# NANO100AN_v1 register map
File version: 1.0
Registers are 32-bit, read-write, reset 0x0 unless marked. A register's access mark holds for its fields unless they carry their own. Offsets are from the block's base; [hi:lo] are bit positions; {n}, {i} and the like mark numbered series; 'fields as' and 'values as' point back to an identical list.

## PWM1 — PWM Register Map
Base 0x40140000
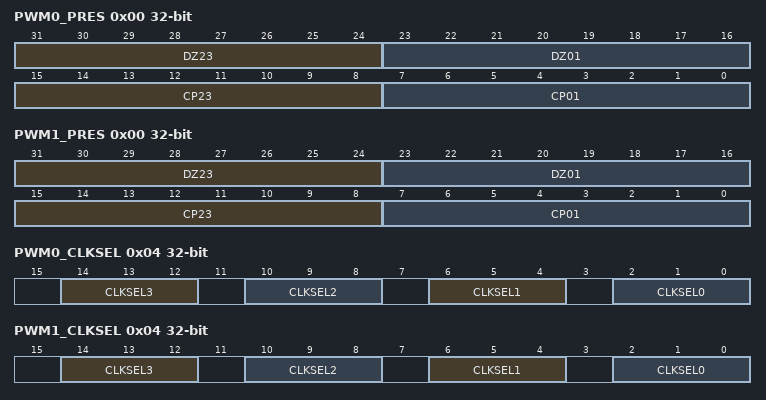
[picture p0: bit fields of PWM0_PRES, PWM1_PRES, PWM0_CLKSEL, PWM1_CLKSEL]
0x00 PWM0_PRES — PWM Prescaler Register
  [31:24] DZ23 — Dead Zone Interval Register For CH2 And CH3 Pair. These 8 bits determine dead zone length. The unit time of dead zone length is received from clock selector 2.
  [23:16] DZ01 — Dead Zone Interval Register For CH0 And CH1 Pair. These 8 bits determine dead zone length. The unit time of dead zone length is received from clock selector 0.
  [15:8] CP23 — Clock Prescaler 2 For PWM Timer 2 3. Clock input is divided by (CP23 + 1) before it is fed to the counter 2 3
  [7:0] CP01 — Clock Prescaler 0 For PWM Timer 0 1. Clock input is divided by (CP01 + 1) before it is fed to the counter 0 1
0x00 PWM1_PRES (alternate view of PWM0_PRES) — PWM Prescaler Register
  fields as PWM0_PRES
0x04 PWM0_CLKSEL — PWM Clock Select Register
  [14:12] CLKSEL3 — Timer 3 Clock Source Selection. Select clock input for timer 3.
    0=input clock is divided by 2; 1=input clock is divided by 4; 2=input clock is divided by 8; 3=input clock is divided by 16; 4=input clock is divided by 1
  [10:8] CLKSEL2 — Timer 2Clock Source Selection. Select clock input for timer 2. (Table is the same as CLKSEL3)
  [6:4] CLKSEL1 — Timer 1 Clock Source Selection. Select clock input for timer 1. (Table is the same as CLKSEL3)
  [2:0] CLKSEL0 — Timer 0 Clock Source Selection. Select clock input for timer 0. (Table is the same as CLKSEL3)
0x04 PWM1_CLKSEL (alternate view of PWM0_CLKSEL) — PWM Clock Select Register
  fields as PWM0_CLKSEL
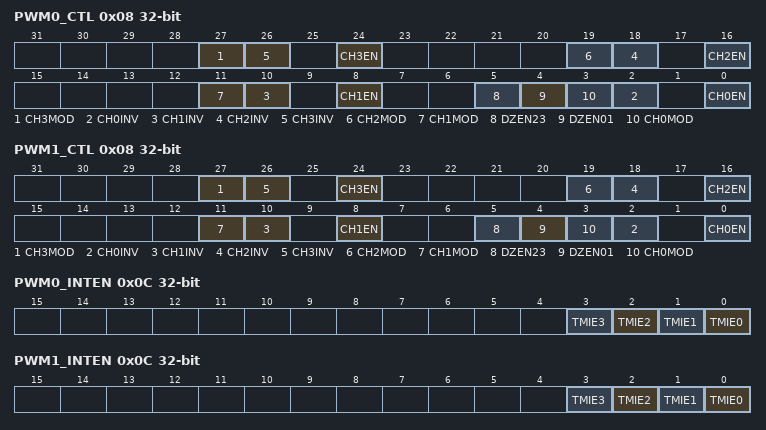
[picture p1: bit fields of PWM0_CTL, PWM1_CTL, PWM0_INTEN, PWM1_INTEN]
0x08 PWM0_CTL — PWM Control Register
  [27] CH3MOD — PWM-Timer 3 Continuous/One-Shot Mode. Note: If there is a rising transition at this bit, it will cause CN and CM of PWMx_DUTY3 to be cleared.
    0=One-shot Mode; 1=Continuous Mode
  [8n+2] CH{n}INV (n=0..3) — PWM-Timer {n} Output Inverter ON/OFF
    0=Inverter OFF; 1=Inverter ON
  [8n] CH{n}EN (n=0..3) — PWM-Timer {n} Enable/Disable Start Run
    0=PWM-Timer {n} Running Stopped; 1=PWM-Timer {n} Start Run Enabled
  [19] CH2MOD — PWM-Timer 2 Continuous/One-Shot Mode. Note: If there is a rising transition at this bit, it will cause CN and CM of PWMx_DUTY2 be cleared.
    0=One-shot Mode; 1=Continuous Mode
  [11] CH1MOD — PWM-Timer 1 Continuous/One-Shot Mode. Note: If there is a rising transition at this bit, it will cause CN and CM of PWMx_DUTY1 to be cleared.
    0=One-shot Mode; 1=Continuous Mode
  [5] DZEN23 — Dead-Zone 2 Generator Enable/Disable. Note: When Dead-Zone Generator is enabled, the pair of PWM2 and PWM3 becomes a complementary pair.
    0=Disabled; 1=Enabled
  [4] DZEN01 — Dead-Zone 0 Generator Enable/Disable. Note: When Dead-Zone Generator is enabled, the pair of PWM0 and PWM1 becomes a complementary pair.
    0=Disabled; 1=Enabled
  [3] CH0MOD — PWM-Timer 0 Continuous/One-Shot Mode. Note: If there is a rising transition at this bit, it will cause CN and CM of PWMx_DUTY0 to be cleared.
    0=One-shot Mode; 1=Continuous Mode
0x08 PWM1_CTL (alternate view of PWM0_CTL) — PWM Control Register
  fields as PWM0_CTL
0x0C PWM0_INTEN — PWM Interrupt Enable Register
  [all] fields
    0=Disabled; 1=Enabled
  [n] TMIE{n} (n=0..3) — PWM Timer {n} Interrupt Enable
0x0C PWM1_INTEN (alternate view of PWM0_INTEN) — PWM Interrupt Enable Register
  fields as PWM0_INTEN
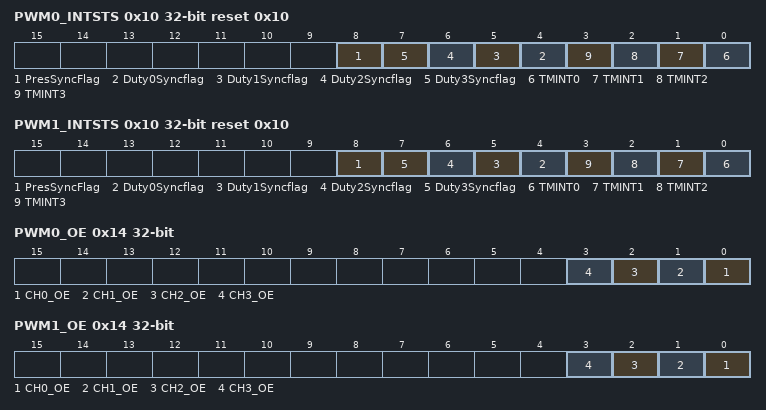
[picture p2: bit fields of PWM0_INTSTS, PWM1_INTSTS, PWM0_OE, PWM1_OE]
0x10 PWM0_INTSTS reset 0x10 — PWM Interrupt Indication Register
  [8] PresSyncFlag — Prescale Synchronize Flag. Note: software should check this flag when writing Prescale, if this flag is set, and user ignore this flag and change Prescale, the Prescale may be wrong for one prescale cycle
    0=Prescale has been synchronized to ECLK domain; 1=Prescale is synchronizing to ECLK domain
  [n+4] Duty{n}Syncflag (n=0..3) — Duty{n} Synchronize Flag. Note: software should check this flag when writing duty{n}, if this flag is set, and user ignore this flag and change duty{n}, the corresponding CNR and CMR may be wrong for one duty cycle
    0=Duty{n} has been synchronized to ECLK domain; 1=Duty{n} is synchronizing to ECLK domain
  [n] TMINT{n} (n=0..3) — PWM Timer {n} Interrupt Flag. Flag is set by hardware when PWM{n} down counter reaches zero, software can clear this bit by writing a one to it.
0x10 PWM1_INTSTS reset 0x10 (alternate view of PWM0_INTSTS) — PWM Interrupt Indication Register
  fields as PWM0_INTSTS
0x14 PWM0_OE — PWM Output Enable Register for CH0 ~ CH3
  [n] CH{n}_OE (n=0..3) — PWM CH{n} Output Enable Register. Note: The corresponding GPIO pin also must be switched to PWM function (refer to GPx_MFP)
    0=PWM CH{n} output to pin Disabled; 1=PWM CH{n} output to pin Enabled
0x14 PWM1_OE (alternate view of PWM0_OE) — PWM Output Enable Register for CH0 ~ CH3
  fields as PWM0_OE
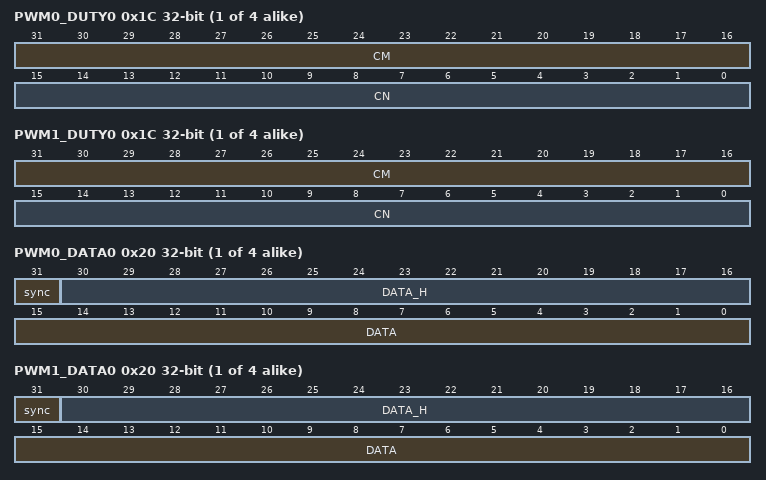
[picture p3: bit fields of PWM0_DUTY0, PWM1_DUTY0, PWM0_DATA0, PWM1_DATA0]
{0x1C+0xC*i} PWM0_DUTY{i} (i=0..3) — PWM Counter/Comparator Register {i}
  [31:16] CM — PWM Comparator Register. CM determines the PWM duty. Note: Any write to CM will take effect in next PWM cycle.
  [15:0] CN — PWM Counter/Timer Loaded Value. CN determines the PWM period. Note: Any write to CN will take effect in next PWM cycle.
{0x1C+0xC*i} PWM1_DUTY{i} (alternate view of PWM0_DUTY{i}) (i=0..3) — PWM Counter/Comparator Register {i}
  fields as PWM0_DUTY0
{0x20+0xC*i} PWM0_DATA{i} ro (i=0..3) — PWM Data Register {i}
  [31] sync — Indicate That CNR Value Is Sync To PWM Counter. Note: when the corresponding cascade enable .bit is set is bit will not appear in the corresponding channel
    0=CNR value is sync to PWM counter; 1=CNR value is not sync to PWM counter
  [30:16] DATA_H — PWM Data Register. User can monitor PWMx_DATAy to know the current value in 32-bit down count counter of corresponding channel y. Notes:This will be valid only for the corresponding cascade enable bit is set
  [15:0] DATA — PWM Data Register. User can monitor PWMx_DATAy to know the current value in 16-bit down count counter of corresponding channel y.
{0x20+0xC*i} PWM1_DATA{i} ro (alternate view of PWM0_DATA{i}) (i=0..3) — PWM Data Register {i}
  fields as PWM0_DATA0
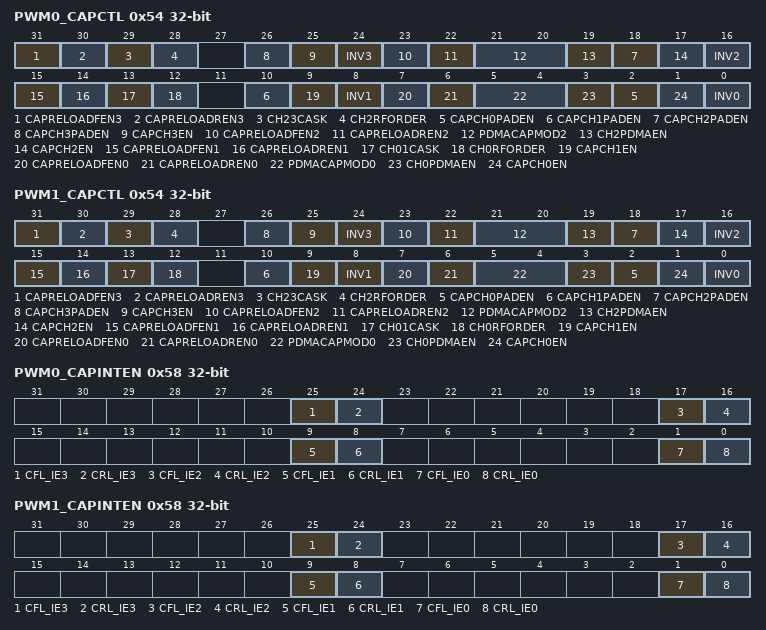
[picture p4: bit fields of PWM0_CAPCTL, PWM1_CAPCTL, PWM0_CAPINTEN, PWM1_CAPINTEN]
0x54 PWM0_CAPCTL — Capture Control Register
  [31] CAPRELOADFEN3 — Reload CNR3 When CH3 Falling Capture Event Comes
    0=Falling capture reload for CH3 Disabled; 1=Falling capture reload for CH3 Enabled
  [30] CAPRELOADREN3 — Reload CNR3 When CH3 Rising Capture Event Comes
    0=Rising capture reload for CH3 Disabled; 1=Rising capture reload for CH3 Enabled
  [29] CH23CASK — Cascade channel 2 and channel 3 PWM counter for capturing usage
  [28] CH2RFORDER
    0=PWMx_CFL2 is the first captured data to memory; 1=PWMx_CRL2 is the first captured data to memory
  [8n+2] CAPCH{n}PADEN (n=0..3) — Capture Input Enable Register
    0=Disable the channel {n} input capture signal from corresponding multi-function pin; 1=Enable the channel {n} input capture signal from corresponding multi-function pin
  [25] CAPCH3EN — Capture Channel 3 Transition Enable/Disable. When Enabled, Capture latched the PMW-timer and saved to PWMx_CRL3 (Rising latch) and PWMx_CFL3 (Falling latch). When Disabled, Capture does not update PWMx_CRL3 and PWMx_CFL3, and disable Channel 3 Interrupt.
    0=Capture function on channel 3 Disabled; 1=Capture function on channel 3 Enabled
  [8n] INV{n} (n=0..3) — Channel {n} Inverter ON/OFF
    0=Inverter OFF; 1=Inverter ON. Reverse the input signal from GPIO before fed to Capture timer
  [23] CAPRELOADFEN2 — Reload CNR2 When CH2 Capture Failing Event Coming
    0=Failing capture reload for CH2 Disabled; 1=Failing capture reload for CH2 Enabled
  [22] CAPRELOADREN2 — Reload CNR2 When CH2 Capture Rising Event Coming
    0=Rising capture reload for CH2 Disabled; 1=Rising capture reload for CH2 Enabled
  [21:20] PDMACAPMOD2 — Select CRL2 Or CFL2 For PDMA Transfer
    1=CRL2 will be transmitted; 2=CFL2 will be transmitted; 3=Both CRL2 and CFL2 will be transmitted
  [19] CH2PDMAEN — Channel 2 PDMA Enable
    0=Channel 2 PDMA function Disabled; 1=Channel 2 PDMA function Enabled for the channel 2 captured data and transfer to memory
  [17] CAPCH2EN — Capture Channel 2 Transition Enable/Disable. When Enabled, Capture latched the PWM-timer value and saved to PWMx_CRL2 (Rising latch) and PWMx_CFL2 (Falling latch). When Disabled, Capture does not update PWMx_CRL2 and PWMx_CFL2, and disable Channel 2 Interrupt.
    0=Capture function on channel 2 Disabled; 1=Capture function on channel 2 Enabled
  [15] CAPRELOADFEN1 — Reload CNR1 When CH1 Capture Falling Event Coming
    0=Capture falling reload for CH1 Disabled; 1=Capture falling reload for CH1 Enabled
  [14] CAPRELOADREN1 — Reload CNR1 When CH1 Capture Rising Event Comes
    0=Rising capture reload for CH1 Disabled; 1=Rising capture reload for CH1 Enabled
  [13] CH01CASK — Cascade channel 0 and channel 1 PWM timer for capturing usage
  [12] CH0RFORDER
    0=PWMx_CFL0 is the first captured data to memory; 1=PWMx_CRL0 is the first captured data to memory
  [9] CAPCH1EN — Capture Channel 1 Transition Enable/Disable. When Enabled, Capture latched the PMW-counter and saved to PWMx_CRL1 (Rising latch) and PWMx_CFL1 (Falling latch). When Disabled, Capture does not update PWMx_CRL1 and PWMx_CFL1, and disable Channel 1 Interrupt.
    0=Capture function on channel 1 Disabled; 1=Capture function on channel 1 Enabled
  [7] CAPRELOADFEN0 — Reload CNR0 When CH0 Capture Falling Event Comes
    0=Falling capture reload for CH0 Disabled; 1=Falling capture reload for CH0 Enabled
  [6] CAPRELOADREN0 — Reload CNR0 When CH0 Capture Rising Event Comes
    0=Rising capture reload for CH0 Disabled; 1=Rising capture reload for CH0 Enabled
  [5:4] PDMACAPMOD0 — Select CRL0 Or CFL0 For PDMA Transfer
    1=CRL0 will be transmitted; 2=CFL0 will be transmitted; 3=Both CRL0 and CFL0 will be transmitted
  [3] CH0PDMAEN — Channel 0 PDMA Enable
    0=Channel 0 PDMA function Disabled; 1=Channel 0 PDMA function Enabled for the channel 0 captured data and transfer to memory
  [1] CAPCH0EN — Capture Channel 0 Transition Enable/Disable. When Enabled, Capture latched the PWM-timer value and saved to PWMx_CRL0 (Rising latch) and PWMx_CFL0 (Falling latch). When Disabled, Capture does not update PWMx_CRL0 and PWMx_CFL0, and disable Channel 0 Interrupt.
    0=Capture function on channel 0 Disabled; 1=Capture function on channel 0 Enabled
0x54 PWM1_CAPCTL (alternate view of PWM0_CAPCTL) — Capture Control Register
  fields as PWM0_CAPCTL
0x58 PWM0_CAPINTEN — Capture Interrupt Enable Register
  [25] CFL_IE3 — Channel 3 Falling Latch Interrupt Enable ON/OFF. When Enabled, if Capture detects Channel 3 has falling transition, Capture issues an Interrupt.
    0=Falling latch interrupt Disabled; 1=Falling latch interrupt Enabled
  [24] CRL_IE3 — Channel 3 Rising Latch Interrupt Enable ON/OFF. When Enabled, if Capture detects Channel 3 has rising transition, Capture issues an Interrupt.
    0=Rising latch interrupt Disabled; 1=Rising latch interrupt Enabled
  [17] CFL_IE2 — Channel 2 Falling Latch Interrupt Enable ON/OFF. When Enabled, if Capture detects Channel 2 has falling transition, Capture issues an Interrupt.
    values as CFL_IE3
  [16] CRL_IE2 — Channel 2 Rising Latch Interrupt Enable ON/OFF. When Enabled, if Capture detects Channel 2 has rising transition, Capture issues an Interrupt.
    values as CRL_IE3
  [9] CFL_IE1 — Channel 1 Falling Latch Interrupt Enable. When Enabled, if Capture detects Channel 1 has falling transition, Capture issues an Interrupt.
    values as CFL_IE3
  [8] CRL_IE1 — Channel 1 Rising Latch Interrupt Enable. When Enabled, if Capture detects Channel 1 has rising transition, Capture issues an Interrupt.
    values as CRL_IE3
  [1] CFL_IE0 — Channel 0 Falling Latch Interrupt Enable ON/OFF. When Enabled, if Capture detects Channel 0 has falling transition, Capture issues an Interrupt.
    values as CFL_IE3
  [0] CRL_IE0 — When Enabled, if Capture detects Channel 0 has rising transition, Capture issues an Interrupt.
    1=Rising latch interrupt Enabled
0x58 PWM1_CAPINTEN (alternate view of PWM0_CAPINTEN) — Capture Interrupt Enable Register
  fields as PWM0_CAPINTEN
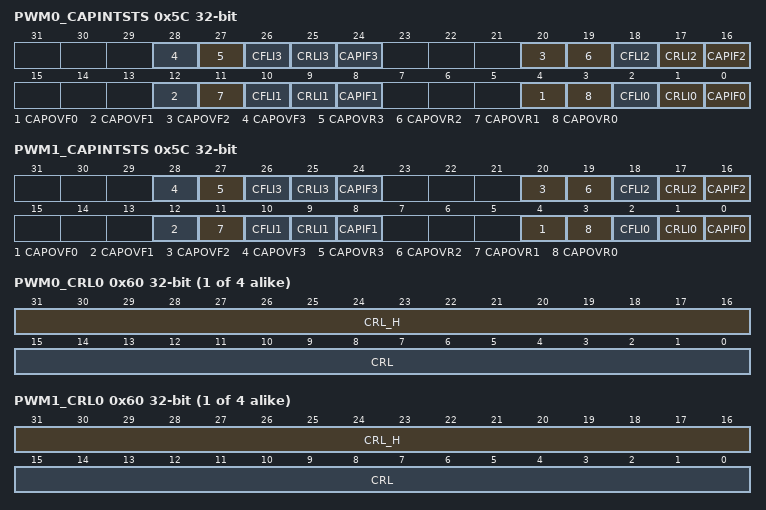
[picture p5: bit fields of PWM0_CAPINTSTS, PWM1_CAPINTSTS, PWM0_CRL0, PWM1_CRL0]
0x5C PWM0_CAPINTSTS — Capture Interrupt Indication Register
  [8n+4] CAPOVF{n} (n=0..3) — Capture Falling Flag Over Run For Channel {n}. This flag indicate CFL{n} update faster than software reading it when it is set. This bit will be cleared automatically when user clear CFLI{n} (PWMx_CAPINTSTS[{8n+2}])
  [27] CAPOVR3 — Capture Rising Flag Over Run For Channel 3. This flag indicate CRL3 update faster than software reading it when it is set. This bit will be cleared automatically when user clear CRLI3 (PWMx_CAPINTSTS[25])
  [26] CFLI3 — PWM_CFL3 Latched Indicator Bit. When input channel 3 has a falling transition, PWMx_CFL3 was latched with the value of PWM down-counter and this bit is set by hardware, software can clear this bit by writing 1 to it.
  [8n+1] CRLI{n} (n=0..3) — PWM_CRL{n} Latched Indicator Bit. When input channel {n} has a rising transition, PWMx_CRL{n} was latched with the value of PWM down-counter and this bit is set by hardware, software can clear this bit by writing 1 to it.
  [8n] CAPIF{n} (n=0..3) — Capture{n} Interrupt Indication Flag. If channel {n} rising latch interrupt (CRL_IE{n}, PWMx_CAPINTEN[{8n}]) is enabled, a rising transition occurs at input channel {n} will result in CAPIF{n} to high; Similarly, a falling transition will cause CAPIF{n} to be set high if channel {n} falling latch interrupt (CFL_IE{n}, PWMx_CAPINTEN[{8n+1}]) is enabled. This flag is cleared by software with a write 1 on it.
  [19] CAPOVR2 — Capture Rising Flag Over Run For Channel 2. This flag indicate CRL2 update faster than software reading it when it is set. This bit will be cleared automatically when user clear CRLI2 (PWMx_CAPINTSTS[17])
  [18] CFLI2 — PWM_CFL2 Latched Indicator Bit. When input channel 2 has a falling transition, PWMx_CFL2 was latched with the value of PWM down-counter and this bit is set by hardware, software can clear this bit by writing 1 to it.
  [11] CAPOVR1 — Capture Rising Flag Over Run For Channel 1. This flag indicate CRL1 update faster than software reading it when it is set. This bit will be cleared automatically when user clear CRLI1 (PWMx_CAPINTSTS[9])
  [10] CFLI1 — PWM_CFL1 Latched Indicator Bit. When input channel 1 has a falling transition, PWMx_CFL1 was latched with the value of PWM down-counter and this bit is set by hardware, software can clear this bit by writing a 1 to it.
  [3] CAPOVR0 — Capture Rising Flag Over Run For Channel 0. This flag indicate CRL0 update faster than software reading it when it is set. This bit will be cleared automatically when user clears CRLI0 (PWMx_CAPINTSTS[1]).
  [2] CFLI0 — PWM_CFL0 Latched Indicator Bit. When input channel 0 has a falling transition, PWMx_CFL0 was latched with the value of PWM down-counter and this bit is set by hardware, software can clear this bit by writing 1 to it.
0x5C PWM1_CAPINTSTS (alternate view of PWM0_CAPINTSTS) — Capture Interrupt Indication Register
  fields as PWM0_CAPINTSTS
{0x60+8i} PWM0_CRL{i} ro (i=0..3) — Capture Rising Latch Register (Channel {i})
  [31:16] CRL_H — Upper Half Word Of 32-Bit Capture Data When Cascade Is Enable. When cascade is enabled for capture channel 0, 2,the original 16 bit counter extend to 32 bit, and capture result CRL0 and CRL2 are also extend to 32 bit,
  [15:0] CRL — Capture Rising Latch Register. Latch the PWM counter when Channel 0/1/2/3 has rising transition.
{0x60+8i} PWM1_CRL{i} ro (alternate view of PWM0_CRL{i}) (i=0..3) — Capture Rising Latch Register (Channel {i})
  fields as PWM0_CRL0
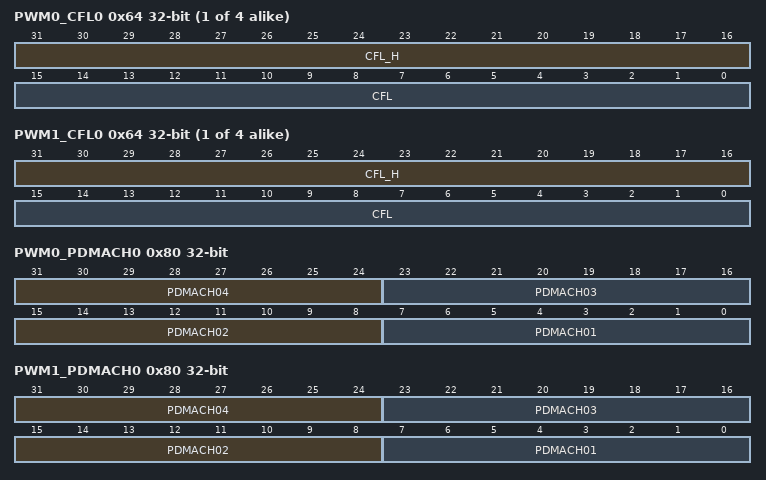
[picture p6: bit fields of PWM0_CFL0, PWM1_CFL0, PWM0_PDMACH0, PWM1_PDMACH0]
{0x64+8i} PWM0_CFL{i} ro (i=0..3) — Capture Falling Latch Register (Channel {i})
  [31:16] CFL_H — Upper Half Word Of 32 Bit Capture Data When Cascade Is Enable. When cascade is enabled for capture channel 0, 2,the original 16 bit counter extend to 32 bit, and capture result CFL0 and CFL2 are also extend to 32 bit,
  [15:0] CFL — Capture Falling Latch Register. Latch the PWM counter when Channel 01/2/3 has Falling transition.
{0x64+8i} PWM1_CFL{i} ro (alternate view of PWM0_CFL{i}) (i=0..3) — Capture Falling Latch Register (Channel {i})
  fields as PWM0_CFL0
0x80 PWM0_PDMACH0 ro — PDMA Channel 0 Captured Data
  [31:24] PDMACH04 — Captured Data Of Channel 0. When CH01CASK is disabled, this byte is 0. When CH01CASK is enabled, It is the fourth byte of 32 bit capturing data for channel 0
  [23:16] PDMACH03 — Captured Data Of Channel 0. When CH01CASK is disabled, this byte is 0. When CH01CASK is enabled, It is the third byte of 32 bit capturing data for channel 0
  [15:8] PDMACH02 — Captured Data Of Channel 0. When CH01CASK is disabled, it is the capturing value(CFL0/CRL0) for channel 0. When CH01CASK is enabled, It is the second byte of 32 bit capturing data for channel 0
  [7:0] PDMACH01 — Captured Data Of Channel 0. When CH01CASK is disabled, it is the capturing value(CFL0/CRL0) for channel 0. When CH01CASK is enabled, It is the for the first byte of 32 bit capturing data for channel 0
0x80 PWM1_PDMACH0 ro (alternate view of PWM0_PDMACH0) — PDMA Channel 0 Captured Data
  fields as PWM0_PDMACH0
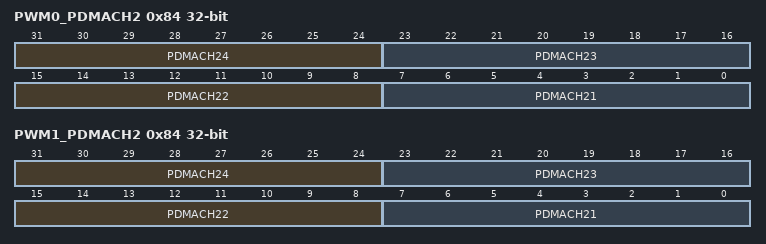
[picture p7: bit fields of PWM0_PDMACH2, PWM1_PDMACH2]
0x84 PWM0_PDMACH2 ro — PDMA Channel 2 Captured Data
  [31:24] PDMACH24 — Captured Data Of Channel 2. When CH23CASK is disabled, this byte is 0. When CH23CASK is enabled, It is the fourth byte of 32 bit capturing data for channel 2
  [23:16] PDMACH23 — Captured Data Of Channel 2. When CH23CASK is disabled, this byte is 0. When CH23CASK is enabled, It is the third byte of 32 bit capturing data for channel 2
  [15:8] PDMACH22 — Captured Data Of Channel 2. When CH23CASK is disabled, it is the capturing value(CFL0/CRL0) for channel 2. When CH23CASK is enabled, It is the second byte of 32 bit capturing data for channel 2
  [7:0] PDMACH21 — Captured Data Of Channel 2. When CH23CASK is disabled, it is the capturing value(CFL0/CRL0) for channel 2. When CH23CASK is enabled, It is the for the first byte of 32 bit capturing data for channel 2
0x84 PWM1_PDMACH2 ro (alternate view of PWM0_PDMACH2) — PDMA Channel 2 Captured Data
  fields as PWM0_PDMACH2
